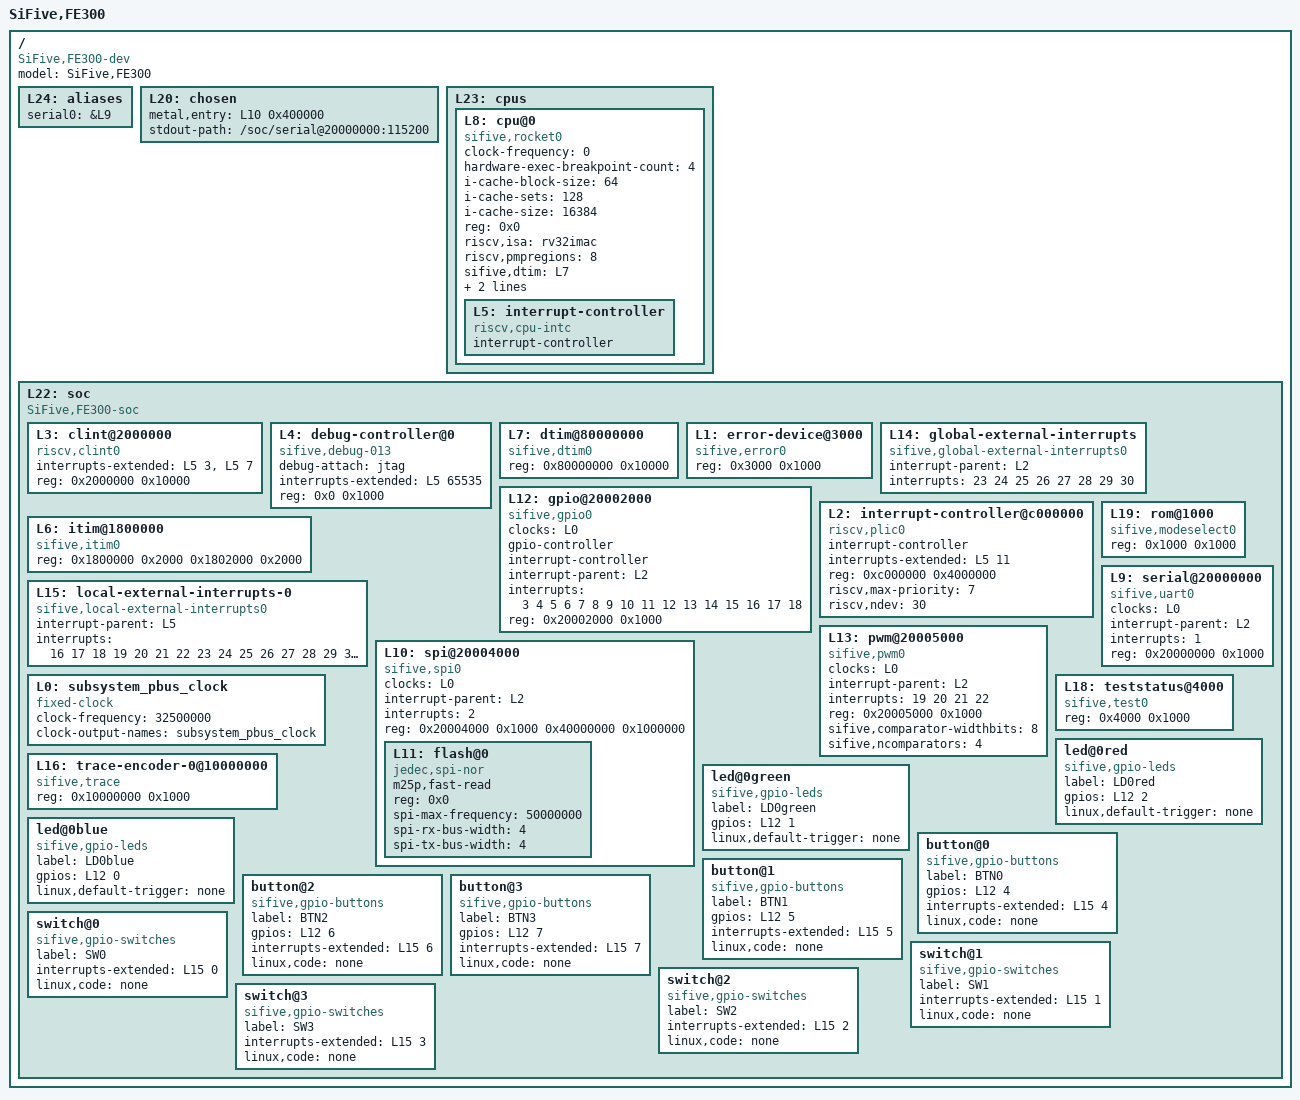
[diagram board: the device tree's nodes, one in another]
/dts-v1/;

/ {
	#address-cells = <1>;
	#size-cells = <1>;
	compatible = "SiFive,FE300-dev", "fe300-dev", "sifive-dev";
	model = "SiFive,FE300";
	L24: aliases {
		serial0 = &L9;
	};
	L20: chosen {
metal,entry = <&L10 0x400000>;
stdout-path="/soc/serial@20000000:115200";
	};
	L23: cpus {
		#address-cells = <1>;
		#size-cells = <0>;
		L8: cpu@0 {
			clock-frequency = <0>;
			compatible = "sifive,rocket0", "riscv";
			device_type = "cpu";
			hardware-exec-breakpoint-count = <4>;
			i-cache-block-size = <64>;
			i-cache-sets = <128>;
			i-cache-size = <16384>;
			reg = <0x0>;
			riscv,isa = "rv32imac";
			riscv,pmpregions = <8>;
			sifive,dtim = <&L7>;
			sifive,itim = <&L6>;
			status = "okay";
			timebase-frequency = <32500000>;
			L5: interrupt-controller {
				#interrupt-cells = <1>;
				compatible = "riscv,cpu-intc";
				interrupt-controller;
			};
		};
	};
	L22: soc {
		#address-cells = <1>;
		#size-cells = <1>;
		compatible = "SiFive,FE300-soc", "fe300-soc", "sifive-soc", "simple-bus";
		ranges;
		L3: clint@2000000 {
			compatible = "riscv,clint0";
			interrupts-extended = <&L5 3 &L5 7>;
			reg = <0x2000000 0x10000>;
			reg-names = "control";
		};
		L4: debug-controller@0 {
			compatible = "sifive,debug-013", "riscv,debug-013";
			debug-attach = "jtag";
			interrupts-extended = <&L5 65535>;
			reg = <0x0 0x1000>;
			reg-names = "control";
		};
		L7: dtim@80000000 {
			compatible = "sifive,dtim0";
			reg = <0x80000000 0x10000>;
			reg-names = "mem";
		};
		L1: error-device@3000 {
			compatible = "sifive,error0";
			reg = <0x3000 0x1000>;
		};
		L14: global-external-interrupts {
			compatible = "sifive,global-external-interrupts0";
			interrupt-parent = <&L2>;
			interrupts = <23 24 25 26 27 28 29 30>;
		};
		L12: gpio@20002000 {
			#gpio-cells = <2>;
			#interrupt-cells = <2>;
			clocks = <&L0>;
			compatible = "sifive,gpio0", "sifive,gpio1";
			gpio-controller;
			interrupt-controller;
			interrupt-parent = <&L2>;
			interrupts = <3 4 5 6 7 8 9 10 11 12 13 14 15 16 17 18>;
			reg = <0x20002000 0x1000>;
			reg-names = "control";
		};
		L2: interrupt-controller@c000000 {
			#interrupt-cells = <1>;
			compatible = "riscv,plic0";
			interrupt-controller;
			interrupts-extended = <&L5 11>;
			reg = <0xc000000 0x4000000>;
			reg-names = "control";
			riscv,max-priority = <7>;
			riscv,ndev = <30>;
		};
		L6: itim@1800000 {
			compatible = "sifive,itim0";
			reg = <0x1800000 0x2000 0x1802000 0x2000>;
			reg-names = "mem", "control";
		};
		L15: local-external-interrupts-0 {
			compatible = "sifive,local-external-interrupts0";
			interrupt-parent = <&L5>;
			interrupts = <16 17 18 19 20 21 22 23 24 25 26 27 28 29 30 31>;
		};
		L13: pwm@20005000 {
			clocks = <&L0>;
			compatible = "sifive,pwm0";
			interrupt-parent = <&L2>;
			interrupts = <19 20 21 22>;
			reg = <0x20005000 0x1000>;
			reg-names = "control";
			sifive,comparator-widthbits = <8>;
			sifive,ncomparators = <4>;
		};
		L19: rom@1000 {
			compatible = "sifive,modeselect0";
			reg = <0x1000 0x1000>;
			reg-names = "mem";
		};
		L9: serial@20000000 {
			clocks = <&L0>;
			compatible = "sifive,uart0";
			interrupt-parent = <&L2>;
			interrupts = <1>;
			reg = <0x20000000 0x1000>;
			reg-names = "control";
		};
		L10: spi@20004000 {
			#address-cells = <1>;
			#size-cells = <0>;
			clocks = <&L0>;
			compatible = "sifive,spi0";
			interrupt-parent = <&L2>;
			interrupts = <2>;
			reg = <0x20004000 0x1000 0x40000000 0x1000000>;
			reg-names = "control", "mem";
			L11: flash@0 {
				compatible = "jedec,spi-nor";
				m25p,fast-read;
				reg = <0x0>;
				spi-max-frequency = <50000000>;
				spi-rx-bus-width = <4>;
				spi-tx-bus-width = <4>;
			};
		};
		L0: subsystem_pbus_clock {
			#clock-cells = <0>;
			clock-frequency = <32500000>;
			clock-output-names = "subsystem_pbus_clock";
			compatible = "fixed-clock";
		};
		L18: teststatus@4000 {
			compatible = "sifive,test0";
			reg = <0x4000 0x1000>;
			reg-names = "control";
		};
		L16: trace-encoder-0@10000000 {
			compatible = "sifive,trace";
			reg = <0x10000000 0x1000>;
			reg-names = "control";
		};
				led@0red {
						compatible = "sifive,gpio-leds";
						label = "LD0red";
						gpios = <&L12 2>;
						linux,default-trigger = "none";
				};
				led@0green {
						compatible = "sifive,gpio-leds";
						label = "LD0green";
						gpios = <&L12 1>;
						linux,default-trigger = "none";
				};
				led@0blue {
						compatible = "sifive,gpio-leds";
						label = "LD0blue";
						gpios = <&L12 0>;
						linux,default-trigger = "none";
				};
				button@0 {
						compatible = "sifive,gpio-buttons";
						label = "BTN0";
						gpios = <&L12 4>;
						interrupts-extended = <&L15 4>;
						linux,code = "none";
				};
				button@1 {
						compatible = "sifive,gpio-buttons";
						label = "BTN1";
						gpios = <&L12 5>;
						interrupts-extended = <&L15 5>;
						linux,code = "none";
				};
				button@2 {
						compatible = "sifive,gpio-buttons";
						label = "BTN2";
						gpios = <&L12 6>;
						interrupts-extended = <&L15 6>;
						linux,code = "none";
				};
				button@3 {
						compatible = "sifive,gpio-buttons";
						label = "BTN3";
						gpios = <&L12 7>;
						interrupts-extended = <&L15 7>;
						linux,code = "none";
				};
				switch@0 {
						compatible = "sifive,gpio-switches";
						label = "SW0";
						interrupts-extended = <&L15 0>;
						linux,code = "none";
				};
				switch@1 {
						compatible = "sifive,gpio-switches";
						label = "SW1";
						interrupts-extended = <&L15 1>;
						linux,code = "none";
				};
				switch@2 {
						compatible = "sifive,gpio-switches";
						label = "SW2";
						interrupts-extended = <&L15 2>;
						linux,code = "none";
				};
				switch@3 {
						compatible = "sifive,gpio-switches";
						label = "SW3";
						interrupts-extended = <&L15 3>;
						linux,code = "none";
				};

	};
};
